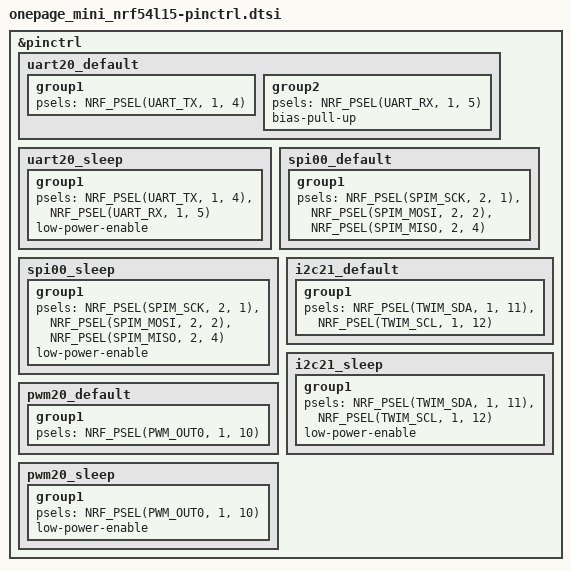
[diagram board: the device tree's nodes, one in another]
/*
 * OnePage Mini pin assignments.
 * Every pin here is a placeholder until the PCB layout is final.
 */
&pinctrl {
	uart20_default: uart20_default {
		group1 {
			psels = <NRF_PSEL(UART_TX, 1, 4)>; /* TODO(pcb) test pad */
		};
		group2 {
			psels = <NRF_PSEL(UART_RX, 1, 5)>; /* TODO(pcb) test pad */
			bias-pull-up;
		};
	};
	uart20_sleep: uart20_sleep {
		group1 {
			psels = <NRF_PSEL(UART_TX, 1, 4)>, <NRF_PSEL(UART_RX, 1, 5)>;
			low-power-enable;
		};
	};
	/* Display and NOR flash share SPIM00. SPIM00 pins must be on port 2. */
	spi00_default: spi00_default {
		group1 {
			psels = <NRF_PSEL(SPIM_SCK, 2, 1)>,  /* TODO(pcb) */
				<NRF_PSEL(SPIM_MOSI, 2, 2)>, /* TODO(pcb) */
				<NRF_PSEL(SPIM_MISO, 2, 4)>; /* TODO(pcb) */
		};
	};
	spi00_sleep: spi00_sleep {
		group1 {
			psels = <NRF_PSEL(SPIM_SCK, 2, 1)>,
				<NRF_PSEL(SPIM_MOSI, 2, 2)>,
				<NRF_PSEL(SPIM_MISO, 2, 4)>;
			low-power-enable;
		};
	};
	/* Touch, fuel gauge and haptic driver share TWIM21. */
	i2c21_default: i2c21_default {
		group1 {
			psels = <NRF_PSEL(TWIM_SDA, 1, 11)>, /* TODO(pcb) */
				<NRF_PSEL(TWIM_SCL, 1, 12)>; /* TODO(pcb) */
		};
	};
	i2c21_sleep: i2c21_sleep {
		group1 {
			psels = <NRF_PSEL(TWIM_SDA, 1, 11)>, <NRF_PSEL(TWIM_SCL, 1, 12)>;
			low-power-enable;
		};
	};
	/* Red status LED. PWM20 can only drive port 1 pins. */
	pwm20_default: pwm20_default {
		group1 {
			psels = <NRF_PSEL(PWM_OUT0, 1, 10)>; /* TODO(pcb) */
		};
	};
	pwm20_sleep: pwm20_sleep {
		group1 {
			psels = <NRF_PSEL(PWM_OUT0, 1, 10)>;
			low-power-enable;
		};
	};
};
